# STM32U3B5xx register map
File version: 1.0
Registers are 32-bit, read-write, reset 0x0 unless marked. A register's access mark holds for its fields unless they carry their own. Offsets are from the block's base; [hi:lo] are bit positions; lines under a group give offsets from that group; {n}, {i} and the like mark numbered series.

## GPIOA — General Purpose I/O
Base 0x42020000
Same registers: GPIOB 0x42020400, GPIOC 0x42020800, GPIOD 0x42020C00, GPIOE 0x42021000, GPIOF 0x42021400, GPIOG 0x42021800, GPIOH 0x42021C00
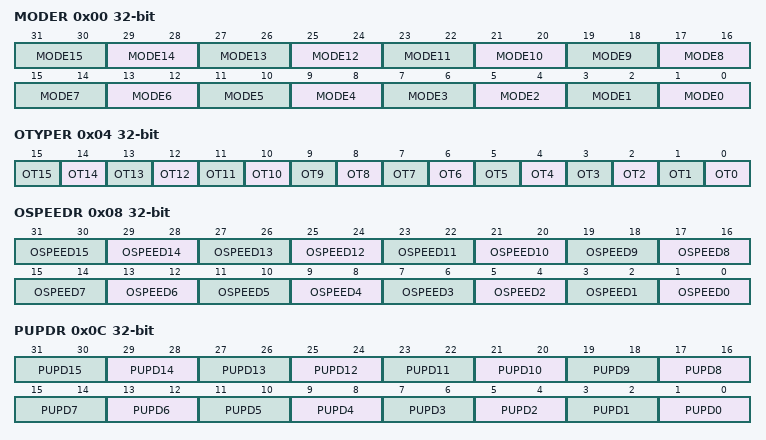
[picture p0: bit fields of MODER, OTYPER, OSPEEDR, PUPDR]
0x00 MODER — GPIO port mode register
  [2n+1:2n] MODE{n} (n=0..15)
0x04 OTYPER — GPIO port output type register
  [n] OT{n} (n=0..15)
0x08 OSPEEDR — GPIO port output speed register
  [2n+1:2n] OSPEED{n} (n=0..15)
0x0C PUPDR — GPIO port pull-up/pull-down register
  [2n+1:2n] PUPD{n} (n=0..15)
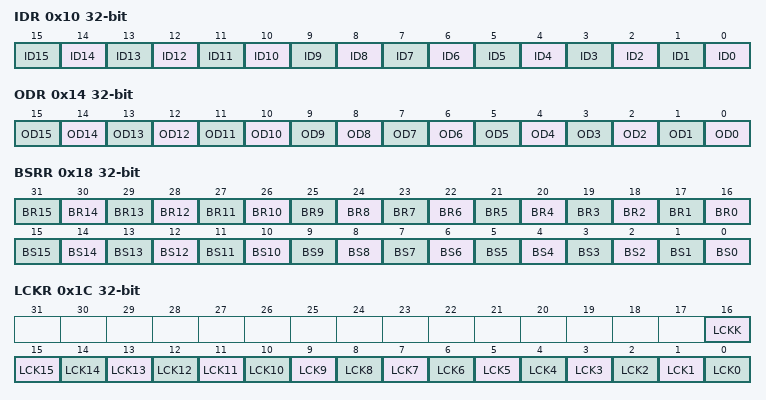
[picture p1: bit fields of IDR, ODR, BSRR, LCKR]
0x10 IDR — GPIO port input data register
  [n] ID{n} (n=0..15)
0x14 ODR — GPIO port output data register
  [n] OD{n} (n=0..15)
0x18 BSRR — GPIO port bit set/reset register
  [n+16] BR{n} (n=0..15), [n] BS{n} (n=0..15)
0x1C LCKR — GPIO port configuration lock register
  [16] LCKK, [n] LCK{n} (n=0..15)
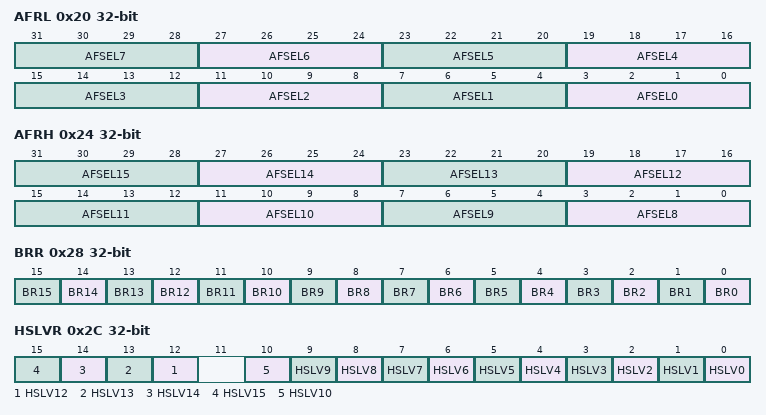
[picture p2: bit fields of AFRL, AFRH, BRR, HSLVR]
0x20 AFRL — GPIO alternate function registers
  [4n+3:4n] AFSEL{n} (n=0..7)
0x24 AFRH — GPIO alternate function registers
  [4n-29:4n-32] AFSEL{n} (n=8..15)
0x28 BRR — GPIO Bit Reset register
  [n] BR{n} (n=0..15)
0x2C HSLVR — GPIO high-speed low voltage register
  [n] HSLV{n} (n=12..15), [n] HSLV{n} (n=0..10)
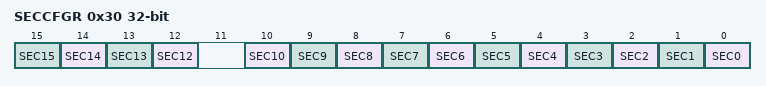
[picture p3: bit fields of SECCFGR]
0x30 SECCFGR — GPIO secure configuration register
  [n] SEC{n} (n=12..15), [n] SEC{n} (n=0..10)

## ADC12_COMMON
Base 0x42028300
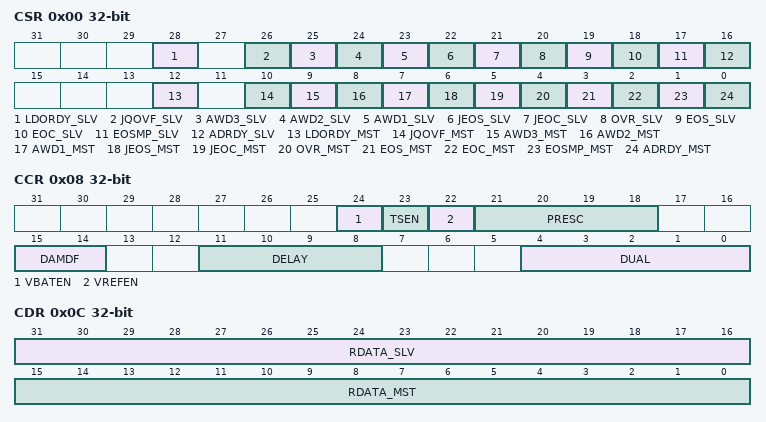
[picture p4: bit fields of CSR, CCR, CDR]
0x00 CSR — ADC common status register
  [28] LDORDY_SLV — ADC multimode slave internal voltage regulator output ready flag
  [26] JQOVF_SLV — ADC multimode slave group injected contexts queue overflow flag
  [25] AWD3_SLV — ADC multimode slave analog watchdog 3 flag
  [24] AWD2_SLV — ADC multimode slave analog watchdog 2 flag
  [23] AWD1_SLV — ADC multimode slave analog watchdog 1 flag
  [22] JEOS_SLV — ADC multimode slave group injected end of sequence conversions flag
  [21] JEOC_SLV — ADC multimode slave group injected end of unitary conversion flag
  [20] OVR_SLV — ADC multimode slave group regular overrun flag
  [19] EOS_SLV — ADC multimode slave group regular end of sequence conversions flag
  [18] EOC_SLV — ADC multimode slave group regular end of unitary conversion flag
  [17] EOSMP_SLV — ADC multimode slave group regular end of sampling flag
  [16] ADRDY_SLV — ADC multimode slave ready flag
  [12] LDORDY_MST — ADC multimode master internal voltage regulator output ready flag
  [10] JQOVF_MST — ADC multimode master group injected contexts queue overflow flag
  [9] AWD3_MST — ADC multimode master analog watchdog 3 flag
  [8] AWD2_MST — ADC multimode master analog watchdog 2 flag
  [7] AWD1_MST — ADC multimode master analog watchdog 1 flag
  [6] JEOS_MST — ADC multimode master group injected end of sequence conversions flag
  [5] JEOC_MST — ADC multimode master group injected end of unitary conversion flag
  [4] OVR_MST — ADC multimode master group regular overrun flag
  [3] EOS_MST — ADC multimode master group regular end of sequence conversions flag
  [2] EOC_MST — ADC multimode master group regular end of unitary conversion flag
  [1] EOSMP_MST — ADC multimode master group regular end of sampling flag
  [0] ADRDY_MST — ADC multimode master ready flag
0x08 CCR — ADC common control register
  [24] VBATEN — ADC internal path to battery voltage enable
  [23] TSEN — ADC internal path to Temperature sensor voltage enable
  [22] VREFEN — ADC internal path to VrefInt enable
  [21:18] PRESC — ADC common clock prescaler
  [15:14] DAMDF — ADC multimode data format
    0=EACH_ADC; 2=COMMON_32B; 3=COMMON_16B
  [11:8] DELAY — ADC multimode delay between 2 sampling phases
    0=DELAY_1CYCLE; {v}=DELAY_{v+1}CYCLES (v=1..12)
  [4:0] DUAL — ADC multimode mode selection
    0=INDEPENDENT; 6=DUAL_REG_SIMULT; 7=DUAL_REG_INTERL; 5=DUAL_INJ_SIMULT; 9=DUAL_INJ_ALTERN; 1=DUAL_REG_SIM_INJ_SIM; 2=DUAL_REG_SIM_INJ_ALT; 3=DUAL_REG_INT_INJ_SIM
0x0C CDR — ADC common regular data register for dual mode
  [31:16] RDATA_SLV — ADC multimode slave group regular conversion data
  [15:0] RDATA_MST — ADC multimode master group regular conversion data
0x10 CDR2 — ADC common regular data register for dual mode 32-bit
  [31:0] RDATA_ALT — ADC multimode master or slave (alternated) group regular conversion data
